# CY8C5667AXI_LP040 register map
File version: 0.1
Registers are 8-bit, read-write, no defined reset value unless marked. A register's access mark holds for its fields unless they carry their own. Offsets are from the block's base; [hi:lo] are bit positions.

## I2C_1
Base 0x00000000
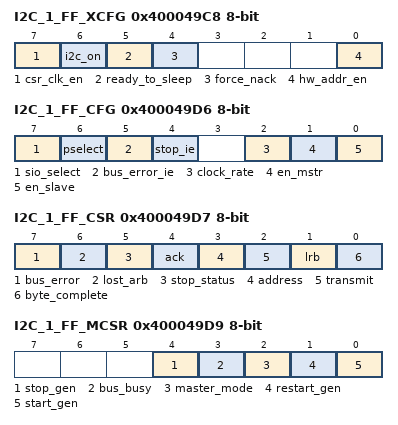
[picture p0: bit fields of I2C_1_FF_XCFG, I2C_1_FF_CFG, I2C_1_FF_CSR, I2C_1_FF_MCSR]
0x400049C8 I2C_1_FF_XCFG — I2C Extended Configuration Register
  [7] csr_clk_en — This bit is used for gating system clock for the blocks core logic that is not associated with AHB interface. Clock is made available to the core logic only when this bit is set to 1 and the input pin ext_clk_en is also active. If either of them is not active, the blocks core logic does not receive the system clock.
  [6] i2c_on — This bit should be set by the user during initial block configuration if the user wants to use the I2C block as wake-up source. Only when this bit set along with other bits mentioned in the sleep mode section, the I2C wakes up system from sleep on address match.
  [5] ready_to_sleep ro — Once the user sets the force_nack bit, the I2C block sets this bit if I2C is not busy or it waits for ongoing transaction to be completed and then sets this bit. As long as this bit is set, the I2C block is going to nack all the transactions.Clearing force_nack bit automatically clears this bit. HW clears this bit automatically on assertion of PD (Power Down)
  [4] force_nack — This bit must be set by the user before putting the device to sleep and wait for ready_to_sleep status bit to be set. This can be cleared by user by writing '0' and the HW clears it automatically on assertion of PD(Power Down)
  [0] hw_addr_en — When this bit is set to a '1', hardware address compare is enabled. On an address match, an interrupt is generated, CSR register bit 3 is set, and the clock is stalled until the CPU writes a 0 into the CSR register bit 3. The address is automatically ACKed on a match. On an address mismatch,no interrupt is generated, clock is not stalled, and bit 3 in the CSR register is set. The CPU must write a 0 into the CSR register bit 3 to clear it. The address is automatically NACKed on a mismatch. You must configure the compare address in the ADR register. When this bit is set to a '0', software address compare is enabled. An interrupt is generated, the clock is stalled, and CSR register bit 3 is set when the received address byte is available in the Data register; to enable the CPU to do a firmware address compare. The clock is stalled until the CPU writes a 0 into the CSR register bit 3. The functionality of this bit is independent of the data buffering mode.
0x400049CA I2C_1_FF_ADDR — I2C Slave Adddress Register
  [6:0] slave_address — These seven bits hold the slave's own device address. These bits are held zero if I2C_CFG.en_mstr and I2C_CFG.en_slave are both zero.
0x400049D6 I2C_1_FF_CFG — I2C Configuration Register
  [7] sio_select — I2C Pin Select for SCL/SDA lines from SIO1/SIO2, 0 = SCL and SDA lines get their inputs from SIO1 module.sclk_str1 and sda_ack1 are driven to SIO1 module and they get asserted once device wakes up from sleep. 1 = SCL and SDA lines get their inputs from SIO2 module. sclk_str2 and sda_ack2 are driven to SIO2 module and they get asserted once device wakes up from sleep. This bit is valid only when I2C.CFG[6] is asserted.
  [6] pselect — I2C Pin Select for SCL/SDA lines from GPIO/SIO, 0 = SCL and SDA lines get their inputs from GPIO module.sclk_str0 and sda_ack0 are driven to GPIO module and they get asserted once device wakes up from sleep. 1 = SCL and SDA lines get their inputs from one of the SIO Blocks that is chosen based on the configuration of bit I2C.CFG[7]
  [5] bus_error_ie — Bus Error Interrupt Enable 0 disabled 1 enabled. An interrupt is generated on the detection of a Bus error condition.
  [4] stop_ie — Stop Interrupt Enable 0 disabled 1 enabled. An interrupt is generated on the detection of a Stop condition.
  [2] clock_rate — 0 Samples/bit is 16, 1 Samples/bit is 32
  [1] en_mstr — Enables master mode for the device
  [0] en_slave — Enables Slave mode for the device
0x400049D7 I2C_1_FF_CSR — I2C Control and Status Register
  [7] bus_error — It must be cleared by firmware by writing a '0' to the bit position. It is never cleared by the hardware. 1 a misplaced Start or Stop condition was detected. This bit is held zero if I2C_CFG.en_mstr and I2C_CFG.en_slave are both zero.
  [6] lost_arb — This bit is set immediately on lost arbitration; however, it does not cause an interrupt. This status may be checked after the following Byte Complete interrupt. Any Start detect or a write to the Start or Restart generate bits (MCSR register), when operating in Master mode, will also clear the bit. 1 lost Arbitration. This bit is held zero if I2C_CFG.en_mstr is zero.
  [5] stop_status — It must be cleared by firmware with write of '0' to the bit position. It is never cleared by the hardware. 1 a Stop condition was detected. This bit is held zero if I2C_CFG.en_mstr and I2C_CFG.en_slave are both zero.
  [4] ack — Acknowledge Out. Bit is automatically cleared by hardware on a Byte Complete event. 0 nack the last received byte. 1 ack the last received byte
  [3] address — It must be cleared by firmware with write of '0' to the bit position. 1 the received byte is a slave address. This bit is held zero if I2C_CFG.en_mstr and I2C_CFG.en_slave are both zero
  [2] transmit — Bit is set by firmware to define the direction of the byte transfer. Any Start detect will clear the bit. 0 receive mode 1 transmit mode. This bit is held zero if I2C_CFG.en_mstr and I2C_CFG.en_slave are both zero.
  [1] lrb — Last Received Bit. The value of the 9th bit in a Transmit sequence, which is the acknowledge bit from the receiver. Any Start detect or a write to the Start or Restart generate bits, when operating in Master mode, will also clear the bit. 0 last transmitted byte was ACK'ed by the receiver. 1 last transmitted byte was NACK'ed by the receiver. This bit is held zero if I2C_CFG.en_mstr and I2C_CFG.en_slave are both zero.
  [0] byte_complete — Transmit/Receive Mode: 0 no completed transmit/receive since last cleared by firmware. Any Start detect or a write to the start or Restart generate bits, when operating in Master mode, will also clear the bit. Transmit mode: 1 eight bits of data have been transmitted and an ACK or NACK has been received. Receive mode: 1 eight bits of data have been received. This bit is held zero if I2C_CFG.en_mstr and I2C_CFG.en_slave are both zero.
0x400049D8 I2C_1_FF_DATA — I2C Data Register
  [7:0] data — Read received data or write data to transmit. These bits are held zero if I2C_CFG.en_mstr and I2C_CFG.en_slave are both zero.
0x400049D9 I2C_1_FF_MCSR — Master Control and Status Register: I2C_MCSR
  [4] stop_gen — This bit is set only for master transmitter and used at the end of byte transfer. After byte complete status is set, if this bit is set followed by the Transmit bit in I2C.CSR register, Stop condition is generated after byte complete. This bit is automatically reset to 0 after the Stop, start or Restart has been generated. During data phase, if Stop Gen bit is set to 0, clearing the Transmit bit in I2C.CSR register will also generate a Stop condition. This bit is held zero if I2C_CFG.en_mstr and I2C_CFG.en_slave are both zero.
  [3] bus_busy ro — This bit is set to the following. 0 when a Stop condition is detected (from any bus master). 1 when a Start condition is detected (from any bus master). This bit is held zero if I2C_CFG.en_mstr and I2C_CFG.en_slave are both zero.
  [2] master_mode ro — This bit is set/cleared by hardware when the device is operating as a master. 0 stop condition detected, generated by this device. 1 start condition detected, generated by this device. This bit is held zero if I2C_CFG.en_mstr and I2C_CFG.en_slave are both zero.
  [1] restart_gen — This bit is cleared by hardware when the Restart generation is complete. 0 restart generation complete. 1 generate a Restart condition. This bit is held zero if I2C_CFG.en_mstr and I2C_CFG.en_slave are both zero.
  [0] start_gen — This bit is cleared by hardware when the Start generation is complete. 0 start generation complete. 1 generate a Start condition and send a byte (address) to the I2C bus, if bus is not busy. This bit is held zero if I2C_CFG.en_mstr and I2C_CFG.en_slave are both zero.
0x400049DB I2C_1_FF_CLK_DIV1 — I2C Clock Divide Factor Register-1
  [7:0] Div — The configuration of this register along with that in register CLK_DIV2 defines the factor by which the SYSCLK will be divided in the I2C block. These bits are held zero if I2C_CFG.en_mstr and I2C_CFG.en_slave are both zero.
0x400049DC I2C_1_FF_CLK_DIV2 — I2C Clock Divide Factor Register-2
  [1:0] Div — The configuration of this register along with that in register CLK_DIV1 defines the factor by whichthe SYSCLK will be divided in the I2C block. These bits are held zero if I2C_CFG.en_mstr and I2C_CFG.en_slave are both zero.
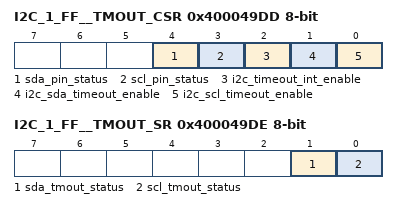
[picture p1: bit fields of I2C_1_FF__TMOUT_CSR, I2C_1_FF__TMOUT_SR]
0x400049DD I2C_1_FF__TMOUT_CSR — I2C Timerout Control and Status Register
  [4] sda_pin_status — SDA Line status.
  [3] scl_pin_status — SCL Line status.
  [2] i2c_timeout_int_enable ro — I2C Timeout interrupt enable.
  [1] i2c_sda_timeout_enable
  [0] i2c_scl_timeout_enable
0x400049DE I2C_1_FF__TMOUT_SR — I2C Timerout Status Register
  [1] sda_tmout_status — SDA Timeout status.
  [0] scl_tmout_status — SCL Timeout status.
0x400049DF I2C_1_FF__TMOUT_CFG0 — I2C Timerout Period Configuration Register-0
  [7:0] timeout_period_lowbyte — The configuration of this register along with that in register TMOUT_CFG1 to define the number units before SCL or SDA stuck low timeout triggers the I2C interrupt. The one unit is equal to SYSCLK/1024. The TMOUT_CFG0 defines lower byte of the period.
0x400049E0 I2C_1_FF__TMOUT_CFG1 — Extended Configuration Register: TMOUT_CFG1
  [3:0] timeout_period_highnibble — The configuration of this register along with that in register TMOUT_CFG1 to define the number units before SCL or SDA stuck low timeout triggers the I2C interrupt. The one unit is equal to SYSCLK/1024. The TMOUT_CFG1 defines higher octet of the period.

## SPIS_1
Base 0x00000000
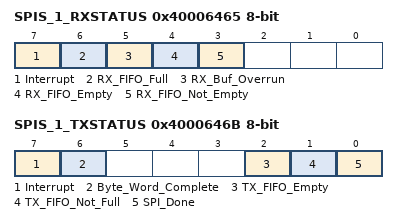
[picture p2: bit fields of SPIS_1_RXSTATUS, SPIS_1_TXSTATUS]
0x40006465 SPIS_1_RXSTATUS — SPIS RX Status Register
  [7] Interrupt ro — Set when interrupt occurs
  [6] RX_FIFO_Full ro — Set when the RX Data FIFO is full
  [5] RX_Buf_Overrun ro — Set when RX Data has overrun the 4 byte/word FIFO without being moved to the RX buffer cmemory array (if one exists)
  [4] RX_FIFO_Empty ro — Set when the RX Data FIFO is empty
  [3] RX_FIFO_Not_Empty ro — Set when the RX Data FIFO is not empty. That is, at least one byte/word is in the RX FIFO
0x4000646B SPIS_1_TXSTATUS — SPIS TX Status Register
  [7] Interrupt ro — Set when interrupt occurs
  [6] Byte_Word_Complete ro — Set when a byte/word transmit has completed
  [2] TX_FIFO_Empty ro — Set when the TX Data FIFO is empty
  [1] TX_FIFO_Not_Full ro — Set when the TX Data FIFO is not full
  [0] SPI_Done ro — Set when all of the data in the transmit FIFO has been sent. Set when Byte/Word Complete has been set and TX Data FIFO is empty
0x40006508 SPIS_1_RX_DATA — SPIS RX Data
0x40006508 SPIS_1_TX_DATA — SPIS TX Data

## RTC_1 — RTC
Base 0x00000000
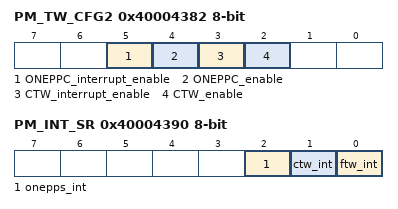
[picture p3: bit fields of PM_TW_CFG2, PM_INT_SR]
0x40004382 PM_TW_CFG2 — Power timers enable and interrupt enable configuration register
  [5] ONEPPC_interrupt_enable — When set and one pulse-per-second is enabled, an interrupt is issued when the pulse occurs
    1=Enabled (The ONEPPC interrupt is issued. Only if ONEPPC is enabled.); 0=Disabled (No ONEPPC interrupt is issued.)
  [4] ONEPPC_enable
    1=Enabled (The ONEPPC is enabled.); 0=Disabled (The ONEPPC is disabled.)
  [3] CTW_interrupt_enable — An interrupt issue when the CTW reaches the selected interval
    1=Enabled (The CTW interrupt is issued. Only if CTW is enabled.); 0=Disabled (No CTW interrupt is issued.)
  [2] CTW_enable
    1=Enabled (The CTW is enabled.); 0=Disabled (The CTW is disabled.)
0x40004390 PM_INT_SR — Power Manager Interrupt Status Register
  [2] onepps_int — When set, a onepps event has occured.
  [1] ctw_int — When set, a limited active ready event has occured
  [0] ftw_int — When set, a fast timewheel event has occured
